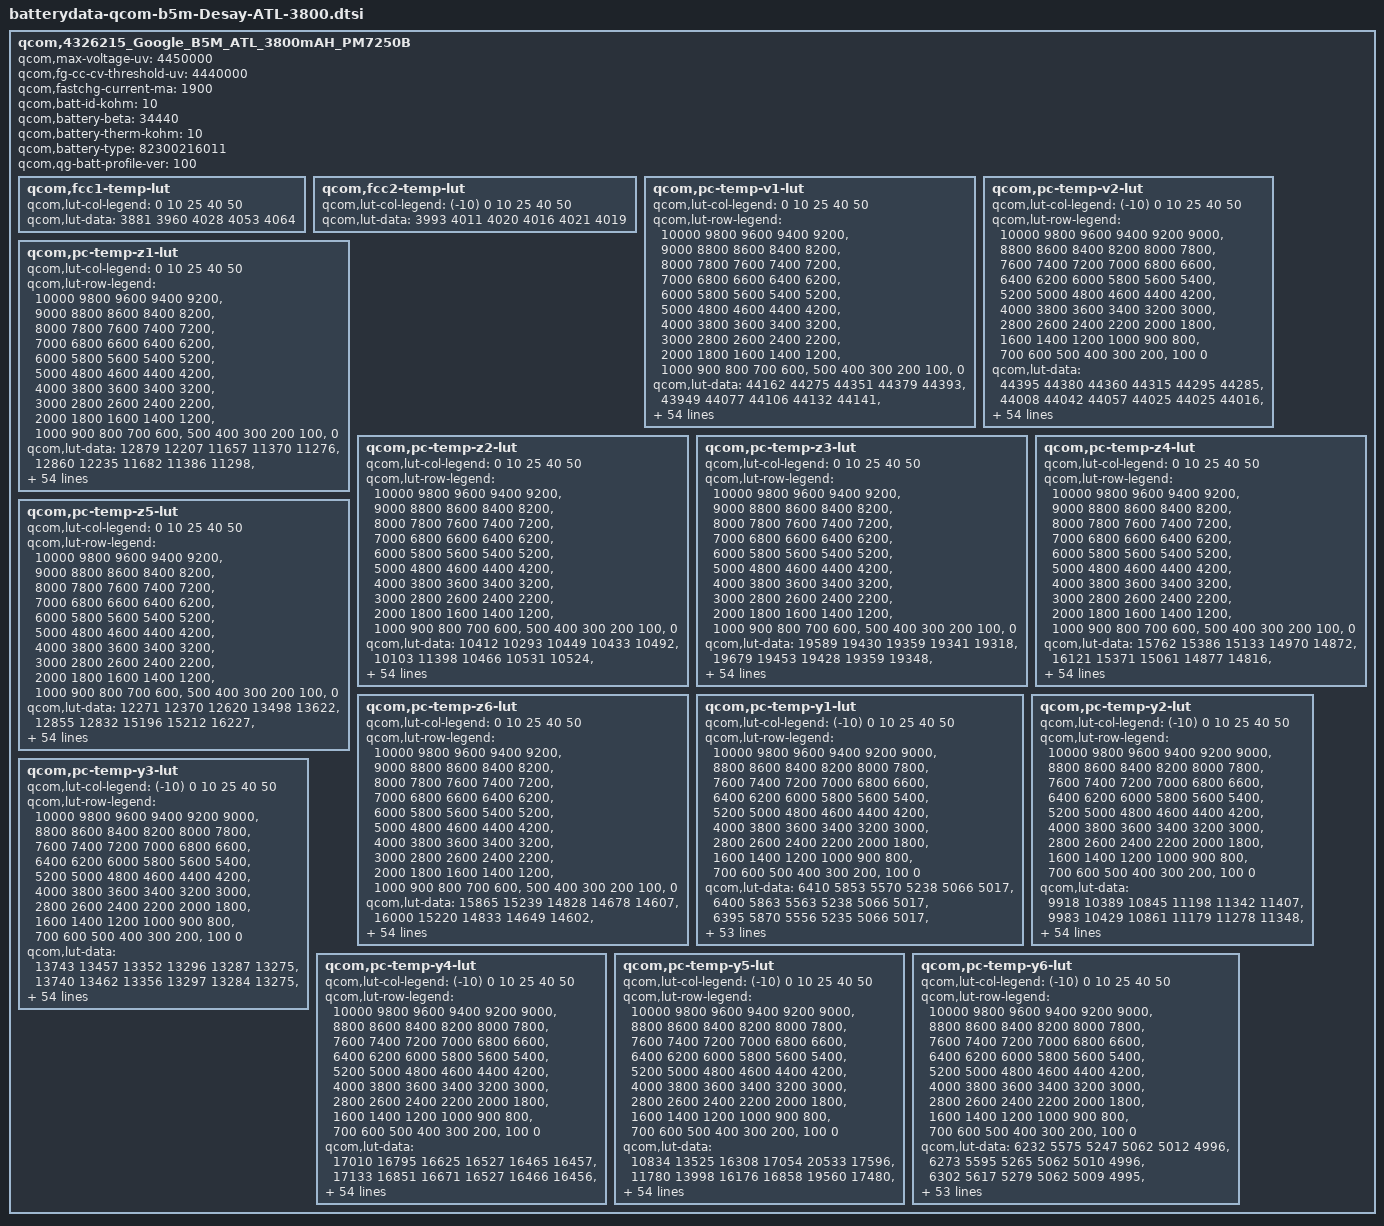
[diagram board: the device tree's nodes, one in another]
// SPDX-License-Identifier: GPL-2.0
qcom,4326215_Google_B5M_ATL_3800mAH_PM7250B {
	/* 4326215_Google_B5M_ATL_3800mAH_PM7250B_Jan23th2020 */
	qcom,max-voltage-uv = <4450000>;
	qcom,fg-cc-cv-threshold-uv = <4440000>;
	qcom,fastchg-current-ma = <1900>;
	qcom,batt-id-kohm = <10>;
	qcom,battery-beta = <34440>;
	qcom,battery-therm-kohm = <10>;
	qcom,battery-type = "82300216011";
	qcom,qg-batt-profile-ver = <100>;

	qcom,fcc1-temp-lut {
		qcom,lut-col-legend = <0 10 25 40 50>;
		qcom,lut-data = <3881 3960 4028 4053 4064>;
	};

	qcom,fcc2-temp-lut {
		qcom,lut-col-legend = <(-10) 0 10 25 40 50>;
		qcom,lut-data = <3993 4011 4020 4016 4021 4019>;
	};

	qcom,pc-temp-v1-lut {
		qcom,lut-col-legend = <0 10 25 40 50>;
		qcom,lut-row-legend = <10000 9800 9600 9400 9200>,
			<9000 8800 8600 8400 8200>,
			<8000 7800 7600 7400 7200>,
			<7000 6800 6600 6400 6200>,
			<6000 5800 5600 5400 5200>,
			<5000 4800 4600 4400 4200>,
			<4000 3800 3600 3400 3200>,
			<3000 2800 2600 2400 2200>,
			<2000 1800 1600 1400 1200>,
			<1000 900 800 700 600>,
			<500 400 300 200 100>,
			<0>;
		qcom,lut-data = <44162 44275 44351 44379 44393>,
			<43949 44077 44106 44132 44141>,
			<43725 43844 43887 43905 43918>,
			<43493 43616 43675 43697 43709>,
			<43258 43401 43453 43481 43498>,
			<43019 43171 43224 43261 43277>,
			<42778 42929 42988 43030 43050>,
			<42536 42687 42747 42789 42816>,
			<42294 42442 42503 42547 42579>,
			<42061 42199 42256 42304 42336>,
			<41836 41963 42013 42062 42093>,
			<41614 41732 41775 41822 41854>,
			<41390 41505 41543 41585 41619>,
			<41170 41280 41314 41354 41387>,
			<40965 41064 41090 41131 41160>,
			<40771 40860 40876 40914 40939>,
			<40573 40663 40671 40703 40726>,
			<40364 40466 40475 40499 40520>,
			<40166 40271 40288 40307 40327>,
			<39999 40086 40107 40122 40143>,
			<39849 39926 39930 39940 39958>,
			<39688 39757 39757 39762 39775>,
			<39518 39509 39552 39568 39581>,
			<39335 39208 39263 39323 39349>,
			<39116 39009 39018 39089 39119>,
			<38890 38882 38896 38937 38955>,
			<38745 38782 38806 38822 38825>,
			<38648 38701 38711 38710 38706>,
			<38573 38631 38616 38601 38596>,
			<38514 38558 38525 38500 38496>,
			<38465 38486 38439 38410 38405>,
			<38418 38417 38360 38329 38321>,
			<38373 38355 38293 38257 38244>,
			<38330 38297 38232 38191 38173>,
			<38289 38248 38179 38129 38104>,
			<38249 38204 38132 38072 38041>,
			<38211 38161 38085 38013 37973>,
			<38174 38124 38042 37952 37896>,
			<38123 38076 37991 37886 37812>,
			<38032 37989 37912 37801 37721>,
			<37917 37870 37801 37696 37621>,
			<37793 37742 37678 37579 37505>,
			<37651 37596 37539 37444 37364>,
			<37481 37428 37377 37287 37209>,
			<37320 37261 37211 37127 37057>,
			<37211 37148 37102 37033 36967>,
			<37182 37117 37075 37008 36947>,
			<37150 37095 37055 36993 36931>,
			<37119 37077 37036 36978 36914>,
			<37078 37039 36999 36931 36859>,
			<36901 36847 36793 36705 36612>,
			<36474 36421 36366 36263 36164>,
			<35885 35835 35787 35682 35583>,
			<35076 35031 34994 34889 34786>,
			<33781 33763 33767 33657 33548>,
			<30000 30000 30000 30000 30000>;
	};

	qcom,pc-temp-v2-lut {
		qcom,lut-col-legend = <(-10) 0 10 25 40 50>;
		qcom,lut-row-legend = <10000 9800 9600 9400 9200 9000>,
			<8800 8600 8400 8200 8000 7800>,
			<7600 7400 7200 7000 6800 6600>,
			<6400 6200 6000 5800 5600 5400>,
			<5200 5000 4800 4600 4400 4200>,
			<4000 3800 3600 3400 3200 3000>,
			<2800 2600 2400 2200 2000 1800>,
			<1600 1400 1200 1000 900 800>,
			<700 600 500 400 300 200>,
			<100 0>;
		qcom,lut-data = <44395 44380 44360 44315 44295 44285>,
			<44008 44042 44057 44025 44025 44016>,
			<43669 43741 43783 43759 43770 43763>,
			<43388 43486 43541 43520 43535 43530>,
			<43152 43268 43328 43304 43318 43314>,
			<42910 43042 43105 43080 43093 43092>,
			<42647 42800 42867 42843 42857 42858>,
			<42390 42554 42625 42603 42618 42621>,
			<42166 42302 42381 42361 42379 42382>,
			<41953 42048 42135 42117 42139 42141>,
			<41696 41810 41894 41878 41901 41903>,
			<41378 41586 41656 41641 41664 41667>,
			<41145 41362 41424 41410 41433 41437>,
			<41040 41127 41192 41184 41204 41211>,
			<40938 40905 40969 40964 40982 40990>,
			<40644 40723 40760 40749 40767 40776>,
			<40127 40560 40560 40540 40558 40567>,
			<39784 40346 40359 40340 40357 40366>,
			<39594 40058 40165 40151 40167 40175>,
			<39415 39773 39953 39959 39978 39986>,
			<39192 39522 39703 39762 39795 39803>,
			<38964 39287 39449 39557 39605 39614>,
			<38762 39072 39226 39328 39376 39387>,
			<38575 38875 39023 39084 39121 39136>,
			<38438 38693 38845 38892 38927 38942>,
			<38344 38521 38689 38745 38783 38795>,
			<38268 38370 38551 38618 38657 38668>,
			<38201 38237 38430 38501 38542 38553>,
			<38142 38125 38319 38396 38437 38449>,
			<38085 38053 38213 38299 38341 38351>,
			<38032 38004 38112 38211 38252 38261>,
			<37977 37959 38022 38128 38171 38177>,
			<37920 37915 37942 38050 38097 38103>,
			<37860 37871 37875 37976 38025 38030>,
			<37798 37823 37828 37912 37953 37952>,
			<37735 37772 37789 37851 37879 37869>,
			<37667 37716 37747 37780 37788 37766>,
			<37593 37656 37703 37698 37678 37640>,
			<37514 37586 37647 37613 37572 37522>,
			<37430 37502 37571 37527 37475 37422>,
			<37337 37403 37476 37440 37383 37329>,
			<37226 37286 37356 37354 37296 37239>,
			<37114 37155 37203 37225 37167 37106>,
			<37013 37000 37046 37096 37040 36978>,
			<36913 36836 36869 36925 36884 36832>,
			<36833 36748 36794 36882 36852 36804>,
			<36794 36722 36767 36866 36842 36791>,
			<36757 36690 36739 36847 36829 36774>,
			<36710 36658 36700 36826 36801 36748>,
			<36632 36593 36624 36760 36726 36657>,
			<36446 36400 36397 36542 36458 36358>,
			<36065 35954 35926 36085 35975 35857>,
			<35513 35307 35276 35462 35338 35210>,
			<34699 34374 34379 34621 34455 34307>,
			<33435 32918 32965 33391 33134 32942>,
			<30879 28130 27743 27850 27863 27776>;
	};

	qcom,pc-temp-z1-lut {
		qcom,lut-col-legend = <0 10 25 40 50>;
		qcom,lut-row-legend = <10000 9800 9600 9400 9200>,
			<9000 8800 8600 8400 8200>,
			<8000 7800 7600 7400 7200>,
			<7000 6800 6600 6400 6200>,
			<6000 5800 5600 5400 5200>,
			<5000 4800 4600 4400 4200>,
			<4000 3800 3600 3400 3200>,
			<3000 2800 2600 2400 2200>,
			<2000 1800 1600 1400 1200>,
			<1000 900 800 700 600>,
			<500 400 300 200 100>,
			<0>;
		qcom,lut-data = <12879 12207 11657 11370 11276>,
			<12860 12235 11682 11386 11298>,
			<12856 12221 11668 11380 11296>,
			<12854 12214 11653 11372 11293>,
			<12853 12204 11639 11366 11290>,
			<12857 12197 11624 11361 11288>,
			<12855 12190 11613 11356 11285>,
			<12844 12183 11604 11351 11283>,
			<12829 12167 11597 11348 11282>,
			<12811 12150 11592 11346 11280>,
			<12789 12135 11588 11344 11279>,
			<12777 12118 11586 11343 11279>,
			<12756 12114 11585 11342 11280>,
			<12731 12115 11583 11341 11280>,
			<12730 12116 11582 11342 11281>,
			<12735 12117 11582 11342 11281>,
			<12737 12117 11583 11343 11282>,
			<12738 12114 11585 11344 11283>,
			<12738 12104 11586 11345 11284>,
			<12728 12100 11588 11348 11286>,
			<12710 12100 11591 11350 11288>,
			<12706 12101 11596 11352 11289>,
			<12723 12103 11600 11354 11290>,
			<12736 12109 11602 11356 11292>,
			<12734 12114 11605 11358 11295>,
			<12729 12123 11610 11362 11298>,
			<12731 12131 11616 11366 11301>,
			<12748 12134 11622 11370 11305>,
			<12757 12137 11628 11375 11309>,
			<12751 12136 11634 11379 11312>,
			<12743 12129 11641 11384 11315>,
			<12742 12127 11648 11389 11318>,
			<12745 12135 11653 11392 11321>,
			<12747 12145 11657 11396 11325>,
			<12753 12153 11661 11400 11328>,
			<12761 12162 11663 11403 11331>,
			<12763 12164 11667 11407 11335>,
			<12762 12161 11677 11411 11337>,
			<12765 12159 11687 11415 11339>,
			<12791 12162 11691 11419 11342>,
			<12819 12170 11693 11422 11344>,
			<12824 12187 11698 11426 11347>,
			<12826 12215 11706 11430 11350>,
			<12826 12215 11715 11434 11353>,
			<12832 12217 11727 11437 11355>,
			<12809 12224 11742 11443 11357>,
			<12826 12223 11735 11444 11358>,
			<12824 12218 11733 11444 11359>,
			<12816 12223 11734 11446 11360>,
			<12850 12223 11740 11450 11362>,
			<12857 12230 11747 11455 11367>,
			<12861 12235 11755 11462 11373>,
			<12867 12273 11766 11471 11381>,
			<12936 12282 11798 11485 11391>,
			<12936 12282 11798 11485 11391>,
			<12936 12282 11798 11485 11391>;
	};

	qcom,pc-temp-z2-lut {
		qcom,lut-col-legend = <0 10 25 40 50>;
		qcom,lut-row-legend = <10000 9800 9600 9400 9200>,
			<9000 8800 8600 8400 8200>,
			<8000 7800 7600 7400 7200>,
			<7000 6800 6600 6400 6200>,
			<6000 5800 5600 5400 5200>,
			<5000 4800 4600 4400 4200>,
			<4000 3800 3600 3400 3200>,
			<3000 2800 2600 2400 2200>,
			<2000 1800 1600 1400 1200>,
			<1000 900 800 700 600>,
			<500 400 300 200 100>,
			<0>;
		qcom,lut-data = <10412 10293 10449 10433 10492>,
			<10103 11398 10466 10531 10524>,
			<10084 10324 10469 10572 10427>,
			<10069 10232 10474 10607 10518>,
			<10053 10213 10440 10594 10611>,
			<10030 10186 10398 10536 10595>,
			<10007 10149 10351 10506 10568>,
			<9988 10122 10305 10489 10501>,
			<9973 10103 10297 10478 10441>,
			<9977 10091 10313 10468 10398>,
			<10025 10096 10331 10461 10366>,
			<10055 10115 10344 10472 10359>,
			<10016 10132 10357 10495 10357>,
			<9964 10145 10369 10488 10362>,
			<9966 10160 10380 10416 10372>,
			<9996 10176 10388 10377 10385>,
			<10015 10193 10399 10382 10406>,
			<10020 10211 10407 10391 10432>,
			<10026 10231 10413 10399 10458>,
			<10042 10241 10422 10414 10484>,
			<10069 10244 10435 10446 10502>,
			<10085 10245 10452 10532 10517>,
			<10095 10252 10458 10577 10531>,
			<10102 10264 10460 10504 10543>,
			<10108 10265 10460 10420 10562>,
			<10113 10247 10437 10452 10648>,
			<10121 10234 10398 10549 10840>,
			<10131 10245 10418 10591 10880>,
			<10141 10264 10525 10607 10698>,
			<10146 10276 10571 10613 10519>,
			<10150 10286 10520 10553 10422>,
			<10156 10290 10468 10479 10361>,
			<10162 10288 10459 10480 10364>,
			<10168 10287 10455 10502 10397>,
			<10173 10289 10462 10535 10436>,
			<10177 10297 10500 10598 10501>,
			<10179 10302 10532 10667 10576>,
			<10181 10306 10549 10735 10700>,
			<10185 10310 10564 10793 10823>,
			<10195 10327 10588 10825 10811>,
			<10204 10346 10615 10848 10737>,
			<10207 10347 10620 10847 10706>,
			<10208 10339 10611 10800 10713>,
			<10226 10346 10609 10782 10695>,
			<10347 10404 10625 10780 10645>,
			<10443 10540 10696 10686 10652>,
			<10278 10530 10666 10647 10655>,
			<10197 10556 10633 10643 10655>,
			<9966 10648 10612 10668 10709>,
			<9761 10689 10634 10739 10766>,
			<9802 10727 10735 10651 10542>,
			<9777 10668 10810 10518 10406>,
			<9781 10558 10844 10449 10366>,
			<9675 10388 10726 10398 10291>,
			<9675 10388 10726 10398 10291>,
			<9675 10388 10726 10398 10291>;
	};

	qcom,pc-temp-z3-lut {
		qcom,lut-col-legend = <0 10 25 40 50>;
		qcom,lut-row-legend = <10000 9800 9600 9400 9200>,
			<9000 8800 8600 8400 8200>,
			<8000 7800 7600 7400 7200>,
			<7000 6800 6600 6400 6200>,
			<6000 5800 5600 5400 5200>,
			<5000 4800 4600 4400 4200>,
			<4000 3800 3600 3400 3200>,
			<3000 2800 2600 2400 2200>,
			<2000 1800 1600 1400 1200>,
			<1000 900 800 700 600>,
			<500 400 300 200 100>,
			<0>;
		qcom,lut-data = <19589 19430 19359 19341 19318>,
			<19679 19453 19428 19359 19348>,
			<19776 19612 19445 19376 19345>,
			<19842 19647 19497 19405 19364>,
			<19871 19659 19513 19422 19393>,
			<19889 19667 19520 19426 19401>,
			<19898 19674 19517 19426 19401>,
			<19900 19676 19511 19424 19391>,
			<19900 19675 19504 19422 19381>,
			<19901 19672 19497 19412 19376>,
			<19909 19663 19489 19401 19372>,
			<19912 19642 19476 19397 19367>,
			<19897 19630 19465 19394 19360>,
			<19871 19623 19460 19388 19355>,
			<19847 19617 19457 19373 19351>,
			<19820 19611 19452 19364 19349>,
			<19810 19605 19441 19363 19347>,
			<19810 19597 19433 19362 19345>,
			<19809 19588 19430 19360 19341>,
			<19799 19584 19427 19359 19335>,
			<19775 19584 19428 19359 19333>,
			<19769 19585 19432 19362 19338>,
			<19780 19592 19435 19364 19341>,
			<19790 19607 19442 19357 19332>,
			<19795 19610 19446 19348 19321>,
			<19799 19598 19432 19343 19334>,
			<19799 19584 19409 19339 19376>,
			<19794 19576 19409 19344 19389>,
			<19787 19570 19428 19384 19387>,
			<19779 19572 19447 19408 19384>,
			<19770 19585 19464 19403 19376>,
			<19764 19594 19475 19395 19364>,
			<19758 19597 19471 19387 19356>,
			<19755 19599 19462 19379 19350>,
			<19753 19597 19454 19374 19346>,
			<19751 19591 19448 19369 19342>,
			<19748 19586 19444 19368 19341>,
			<19743 19580 19441 19368 19343>,
			<19737 19574 19439 19369 19347>,
			<19729 19567 19435 19369 19346>,
			<19720 19560 19430 19368 19344>,
			<19711 19555 19426 19365 19344>,
			<19699 19551 19421 19360 19346>,
			<19679 19542 19417 19360 19346>,
			<19619 19519 19411 19362 19342>,
			<19462 19476 19394 19344 19333>,
			<19354 19472 19393 19345 19326>,
			<19327 19456 19389 19342 19325>,
			<19299 19363 19385 19335 19320>,
			<19276 19346 19367 19329 19321>,
			<19267 19349 19377 19344 19341>,
			<19300 19337 19350 19354 19347>,
			<19332 19321 19333 19357 19348>,
			<19343 19318 19342 19361 19353>,
			<19343 19318 19342 19361 19353>,
			<19343 19318 19342 19361 19353>;
	};

	qcom,pc-temp-z4-lut {
		qcom,lut-col-legend = <0 10 25 40 50>;
		qcom,lut-row-legend = <10000 9800 9600 9400 9200>,
			<9000 8800 8600 8400 8200>,
			<8000 7800 7600 7400 7200>,
			<7000 6800 6600 6400 6200>,
			<6000 5800 5600 5400 5200>,
			<5000 4800 4600 4400 4200>,
			<4000 3800 3600 3400 3200>,
			<3000 2800 2600 2400 2200>,
			<2000 1800 1600 1400 1200>,
			<1000 900 800 700 600>,
			<500 400 300 200 100>,
			<0>;
		qcom,lut-data = <15762 15386 15133 14970 14872>,
			<16121 15371 15061 14877 14816>,
			<16058 15522 14960 14820 14773>,
			<15811 15451 15098 14871 14782>,
			<15618 15269 15037 14883 14825>,
			<15457 15151 14950 14841 14791>,
			<15323 15065 14903 14806 14767>,
			<15221 14997 14866 14774 14753>,
			<15138 14941 14834 14756 14742>,
			<15057 14895 14802 14750 14735>,
			<14971 14859 14783 14746 14729>,
			<14920 14828 14774 14736 14723>,
			<14903 14810 14768 14724 14718>,
			<14892 14799 14758 14720 14712>,
			<14875 14791 14745 14719 14704>,
			<14849 14780 14738 14717 14696>,
			<14835 14772 14735 14709 14686>,
			<14831 14772 14732 14697 14678>,
			<14828 14775 14725 14688 14673>,
			<14824 14777 14719 14681 14669>,
			<14817 14762 14719 14680 14668>,
			<14811 14746 14721 14684 14673>,
			<14803 14786 14731 14693 14682>,
			<14798 14888 14824 14768 14744>,
			<14841 14926 14901 14849 14821>,
			<14922 14935 14903 14853 14810>,
			<14942 14938 14903 14847 14756>,
			<14941 14927 14895 14832 14724>,
			<14939 14902 14854 14771 14708>,
			<14927 14877 14815 14726 14699>,
			<14907 14846 14778 14714 14694>,
			<14890 14824 14754 14707 14690>,
			<14873 14809 14750 14701 14684>,
			<14858 14800 14748 14696 14678>,
			<14845 14797 14748 14696 14677>,
			<14833 14795 14749 14698 14679>,
			<14820 14792 14751 14701 14683>,
			<14805 14787 14753 14709 14694>,
			<14799 14783 14756 14718 14705>,
			<14797 14784 14762 14723 14706>,
			<14795 14786 14769 14727 14706>,
			<14788 14782 14768 14727 14704>,
			<14773 14763 14754 14721 14695>,
			<14760 14749 14744 14716 14695>,
			<14753 14729 14733 14711 14699>,
			<14823 14697 14694 14688 14677>,
			<14941 14691 14684 14677 14671>,
			<14966 14696 14667 14660 14651>,
			<14987 14787 14657 14647 14638>,
			<15002 14801 14670 14653 14637>,
			<15006 14807 14680 14659 14639>,
			<14995 14831 14719 14657 14639>,
			<14978 14854 14738 14654 14638>,
			<14987 14865 14731 14651 14633>,
			<14987 14865 14731 14651 14633>,
			<14987 14865 14731 14651 14633>;
	};

	qcom,pc-temp-z5-lut {
		qcom,lut-col-legend = <0 10 25 40 50>;
		qcom,lut-row-legend = <10000 9800 9600 9400 9200>,
			<9000 8800 8600 8400 8200>,
			<8000 7800 7600 7400 7200>,
			<7000 6800 6600 6400 6200>,
			<6000 5800 5600 5400 5200>,
			<5000 4800 4600 4400 4200>,
			<4000 3800 3600 3400 3200>,
			<3000 2800 2600 2400 2200>,
			<2000 1800 1600 1400 1200>,
			<1000 900 800 700 600>,
			<500 400 300 200 100>,
			<0>;
		qcom,lut-data = <12271 12370 12620 13498 13622>,
			<12855 12832 15196 15212 16227>,
			<13441 14638 17001 17601 17130>,
			<14178 15226 15937 17602 18662>,
			<14739 15715 16525 17395 18262>,
			<15166 16254 17258 17735 19519>,
			<15622 16850 17453 18235 19819>,
			<16183 17527 17551 19181 19231>,
			<16783 18400 17869 19605 18807>,
			<17522 19276 18886 19101 18826>,
			<18741 19933 19469 18580 18871>,
			<19583 20520 19266 18845 18688>,
			<19925 21135 19030 19450 18310>,
			<20188 21795 19394 19377 18219>,
			<20469 22480 20407 18205 18471>,
			<21046 23363 20687 17572 18849>,
			<21908 24141 20430 18125 19739>,
			<23772 24203 20254 19075 20658>,
			<25260 24021 20682 19959 20662>,
			<24820 23998 21679 20971 20445>,
			<23653 26219 23242 22346 20701>,
			<23935 30062 25745 24514 23551>,
			<30727 35285 27447 25512 25467>,
			<37839 41670 28692 22936 21587>,
			<41162 42443 29362 19136 16410>,
			<43607 34873 25565 16806 16453>,
			<43438 27754 19132 14977 18238>,
			<39674 24709 18173 15020 19808>,
			<35804 22760 18627 18194 21307>,
			<33163 22924 19523 21084 22047>,
			<31151 24965 23507 22378 21909>,
			<30579 27407 27991 23413 21718>,
			<30359 30491 30173 24536 22063>,
			<30353 33415 31727 25659 23366>,
			<31260 35191 32844 26913 24595>,
			<32567 36537 33832 28550 25851>,
			<33297 36878 34197 29359 26566>,
			<34046 36302 33575 29196 26685>,
			<34645 35530 32355 28791 26743>,
			<35222 34190 30205 27488 25845>,
			<35590 32479 27064 24620 23134>,
			<34631 31845 25547 22753 22302>,
			<32155 31607 24932 21659 22850>,
			<30452 30278 24057 21308 22198>,
			<26725 29273 23437 21176 19916>,
			<17720 28760 25668 20481 20287>,
			<12744 26637 25899 21750 19193>,
			<11828 22385 26812 23292 21956>,
			<11538 13967 27355 24606 24930>,
			<11315 13049 21421 21938 25073>,
			<11341 13183 19714 20306 25180>,
			<11527 12669 15316 20559 25094>,
			<11701 12154 13647 20896 24773>,
			<11662 11957 13824 21171 26887>,
			<11662 11957 13824 21171 26887>,
			<11662 11957 13824 21171 26887>;
	};

	qcom,pc-temp-z6-lut {
		qcom,lut-col-legend = <0 10 25 40 50>;
		qcom,lut-row-legend = <10000 9800 9600 9400 9200>,
			<9000 8800 8600 8400 8200>,
			<8000 7800 7600 7400 7200>,
			<7000 6800 6600 6400 6200>,
			<6000 5800 5600 5400 5200>,
			<5000 4800 4600 4400 4200>,
			<4000 3800 3600 3400 3200>,
			<3000 2800 2600 2400 2200>,
			<2000 1800 1600 1400 1200>,
			<1000 900 800 700 600>,
			<500 400 300 200 100>,
			<0>;
		qcom,lut-data = <15865 15239 14828 14678 14607>,
			<16000 15220 14833 14649 14602>,
			<15973 15341 14792 14634 14582>,
			<15861 15309 14873 14669 14595>,
			<15764 15218 14850 14681 14626>,
			<15674 15157 14815 14665 14618>,
			<15596 15111 14790 14651 14609>,
			<15530 15072 14768 14637 14597>,
			<15474 15038 14748 14625 14587>,
			<15427 15008 14730 14617 14581>,
			<15386 14977 14715 14609 14576>,
			<15351 14949 14705 14602 14570>,
			<15323 14932 14696 14596 14564>,
			<15299 14923 14688 14589 14558>,
			<15270 14915 14681 14582 14553>,
			<15240 14907 14674 14575 14548>,
			<15227 14899 14667 14570 14543>,
			<15225 14894 14662 14565 14538>,
			<15223 14891 14657 14560 14533>,
			<15215 14887 14654 14556 14528>,
			<15202 14881 14654 14556 14528>,
			<15198 14877 14657 14559 14531>,
			<15202 14899 14665 14566 14538>,
			<15209 14954 14710 14595 14562>,
			<15232 14971 14746 14625 14588>,
			<15268 14970 14742 14625 14591>,
			<15277 14968 14732 14622 14589>,
			<15278 14960 14726 14619 14587>,
			<15277 14949 14721 14614 14581>,
			<15270 14941 14717 14609 14574>,
			<15259 14935 14712 14602 14567>,
			<15250 14932 14708 14595 14560>,
			<15242 14930 14704 14589 14553>,
			<15236 14928 14700 14582 14547>,
			<15232 14927 14698 14580 14545>,
			<15229 14925 14696 14580 14545>,
			<15226 14924 14696 14579 14545>,
			<15224 14922 14697 14583 14550>,
			<15223 14921 14698 14588 14557>,
			<15226 14922 14700 14591 14558>,
			<15230 14924 14702 14592 14557>,
			<15229 14924 14701 14592 14556>,
			<15228 14921 14695 14586 14554>,
			<15222 14917 14691 14585 14554>,
			<15199 14907 14687 14586 14555>,
			<15164 14880 14665 14567 14541>,
			<15158 14877 14661 14562 14535>,
			<15157 14871 14653 14553 14526>,
			<15156 14867 14646 14544 14517>,
			<15158 14867 14646 14544 14517>,
			<15166 14878 14657 14556 14530>,
			<15185 14889 14664 14562 14535>,
			<15206 14900 14668 14565 14537>,
			<15237 14917 14675 14568 14541>,
			<15237 14917 14675 14568 14541>,
			<15237 14917 14675 14568 14541>;
	};

	qcom,pc-temp-y1-lut {
		qcom,lut-col-legend = <(-10) 0 10 25 40 50>;
		qcom,lut-row-legend = <10000 9800 9600 9400 9200 9000>,
			<8800 8600 8400 8200 8000 7800>,
			<7600 7400 7200 7000 6800 6600>,
			<6400 6200 6000 5800 5600 5400>,
			<5200 5000 4800 4600 4400 4200>,
			<4000 3800 3600 3400 3200 3000>,
			<2800 2600 2400 2200 2000 1800>,
			<1600 1400 1200 1000 900 800>,
			<700 600 500 400 300 200>,
			<100 0>;
		qcom,lut-data = <6410 5853 5570 5238 5066 5017>,
			<6400 5863 5563 5238 5066 5017>,
			<6395 5870 5556 5235 5066 5017>,
			<6391 5875 5551 5232 5065 5017>,
			<6390 5878 5547 5229 5064 5016>,
			<6390 5878 5545 5227 5063 5016>,
			<6396 5874 5545 5225 5061 5014>,
			<6402 5872 5546 5223 5059 5013>,
			<6412 5876 5543 5220 5058 5013>,
			<6428 5885 5540 5216 5057 5013>,
			<6430 5890 5541 5212 5056 5013>,
			<6422 5895 5547 5206 5054 5013>,
			<6414 5896 5550 5204 5053 5013>,
			<6404 5893 5549 5206 5053 5012>,
			<6396 5888 5547 5208 5054 5011>,
			<6396 5883 5543 5207 5054 5011>,
			<6398 5877 5538 5205 5053 5012>,
			<6402 5877 5537 5205 5053 5012>,
			<6419 5889 5538 5207 5053 5012>,
			<6432 5896 5539 5209 5052 5012>,
			<6431 5892 5538 5211 5053 5013>,
			<6425 5887 5538 5213 5055 5014>,
			<6422 5887 5539 5216 5056 5014>,
			<6416 5889 5541 5220 5058 5015>,
			<6415 5891 5542 5224 5060 5016>,
			<6436 5898 5544 5227 5063 5018>,
			<6457 5903 5546 5229 5065 5020>,
			<6455 5903 5549 5233 5066 5021>,
			<6451 5902 5552 5237 5067 5022>,
			<6447 5901 5553 5242 5069 5023>,
			<6444 5899 5554 5247 5072 5025>,
			<6438 5900 5555 5253 5076 5027>,
			<6419 5902 5560 5258 5079 5030>,
			<6399 5904 5565 5263 5082 5032>,
			<6404 5906 5570 5266 5085 5034>,
			<6422 5907 5575 5270 5088 5036>,
			<6430 5909 5579 5273 5091 5038>,
			<6429 5915 5583 5277 5093 5039>,
			<6427 5918 5587 5281 5095 5041>,
			<6423 5919 5590 5288 5098 5043>,
			<6417 5919 5592 5292 5100 5045>,
			<6408 5914 5588 5291 5101 5047>,
			<6432 5932 5598 5301 5106 5048>,
			<6464 5953 5610 5297 5107 5050>,
			<6490 5973 5610 5305 5112 5052>,
			<6495 5957 5604 5313 5111 5054>,
			<6480 5937 5614 5311 5113 5054>,
			<6485 5952 5611 5313 5114 5054>,
			<6509 5966 5619 5317 5113 5054>,
			<6569 5988 5612 5322 5114 5055>,
			<6618 5981 5619 5326 5116 5057>,
			<6641 6006 5634 5332 5119 5060>,
			<6728 6097 5651 5347 5126 5067>,
			<6812 6167 5695 5356 5134 5072>,
			<6812 6167 5695 5356 5134 5072>,
			<6812 6167 5695 5356 5134 5072>;
	};

	qcom,pc-temp-y2-lut {
		qcom,lut-col-legend = <(-10) 0 10 25 40 50>;
		qcom,lut-row-legend = <10000 9800 9600 9400 9200 9000>,
			<8800 8600 8400 8200 8000 7800>,
			<7600 7400 7200 7000 6800 6600>,
			<6400 6200 6000 5800 5600 5400>,
			<5200 5000 4800 4600 4400 4200>,
			<4000 3800 3600 3400 3200 3000>,
			<2800 2600 2400 2200 2000 1800>,
			<1600 1400 1200 1000 900 800>,
			<700 600 500 400 300 200>,
			<100 0>;
		qcom,lut-data = <9918 10389 10845 11198 11342 11407>,
			<9983 10429 10861 11179 11278 11348>,
			<10063 10486 10868 11157 11199 11288>,
			<10142 10545 10868 11131 11123 11231>,
			<10205 10587 10864 11102 11066 11178>,
			<10237 10598 10857 11071 11046 11132>,
			<10248 10590 10838 11030 11049 11090>,
			<10260 10583 10817 11001 11051 11052>,
			<10312 10589 10796 10997 11035 11011>,
			<10392 10601 10778 10996 11013 10976>,
			<10415 10606 10776 10997 11017 10974>,
			<10403 10602 10781 11001 11054 10991>,
			<10394 10606 10788 11004 11078 11011>,
			<10395 10676 10802 11011 11090 11042>,
			<10390 10748 10825 11021 11096 11065>,
			<10223 10748 10868 11038 11081 11055>,
			<9810 10728 10933 11068 11048 11031>,
			<9679 10743 10984 11108 11051 11032>,
			<9677 10813 11032 11174 11123 11096>,
			<9675 10852 11051 11230 11219 11159>,
			<9672 10846 11034 11275 11377 11268>,
			<9669 10833 11014 11306 11509 11374>,
			<9667 10821 11013 11285 11454 11346>,
			<9666 10806 11017 11224 11296 11255>,
			<9664 10782 11021 11207 11252 11230>,
			<9663 10727 11026 11230 11265 11247>,
			<9662 10670 11033 11256 11282 11275>,
			<9662 10505 11044 11274 11307 11342>,
			<9661 10270 11056 11294 11336 11425>,
			<9660 10144 11047 11324 11359 11458>,
			<9660 9880 11010 11366 11391 11479>,
			<9659 9744 10991 11386 11422 11487>,
			<9659 9709 10986 11392 11488 11515>,
			<9659 9690 10980 11394 11540 11541>,
			<9658 9680 10964 11387 11555 11548>,
			<9658 9675 10935 11367 11566 11553>,
			<9658 9670 10901 11341 11549 11530>,
			<9658 9666 10851 11302 11474 11459>,
			<9658 9663 10791 11284 11420 11427>,
			<9657 9661 10713 11296 11388 11437>,
			<9657 9659 10621 11297 11376 11441>,
			<9657 9658 10512 11265 11390 11438>,
			<9657 9658 10217 11254 11438 11417>,
			<9656 9658 10155 11279 11413 11372>,
			<9656 9657 9849 11143 11393 11450>,
			<9655 9655 9740 11108 11273 11194>,
			<9655 9655 9717 11083 11282 11184>,
			<9654 9655 9695 11080 11287 11151>,
			<9653 9654 9683 11056 11270 11118>,
			<9651 9654 9672 11047 11156 11086>,
			<9649 9653 9666 10994 11127 11052>,
			<9648 9651 9661 10956 11134 11024>,
			<9648 9649 9656 10896 11045 10972>,
			<9648 9648 9653 10819 10989 10858>,
			<9648 9648 9653 10819 10989 10858>,
			<9648 9648 9653 10819 10989 10858>;
	};

	qcom,pc-temp-y3-lut {
		qcom,lut-col-legend = <(-10) 0 10 25 40 50>;
		qcom,lut-row-legend = <10000 9800 9600 9400 9200 9000>,
			<8800 8600 8400 8200 8000 7800>,
			<7600 7400 7200 7000 6800 6600>,
			<6400 6200 6000 5800 5600 5400>,
			<5200 5000 4800 4600 4400 4200>,
			<4000 3800 3600 3400 3200 3000>,
			<2800 2600 2400 2200 2000 1800>,
			<1600 1400 1200 1000 900 800>,
			<700 600 500 400 300 200>,
			<100 0>;
		qcom,lut-data = <13743 13457 13352 13296 13287 13275>,
			<13740 13462 13356 13297 13284 13275>,
			<13736 13468 13360 13298 13281 13275>,
			<13730 13473 13364 13299 13280 13275>,
			<13723 13477 13368 13300 13279 13276>,
			<13715 13480 13370 13302 13279 13276>,
			<13703 13482 13372 13303 13280 13277>,
			<13695 13483 13373 13305 13281 13278>,
			<13693 13483 13375 13305 13284 13279>,
			<13691 13484 13376 13304 13288 13280>,
			<13670 13485 13378 13305 13290 13280>,
			<13578 13494 13380 13305 13291 13281>,
			<13528 13497 13380 13306 13291 13281>,
			<13536 13458 13380 13310 13291 13285>,
			<13549 13416 13379 13313 13291 13287>,
			<13558 13421 13372 13312 13290 13287>,
			<13566 13437 13359 13310 13288 13287>,
			<13573 13439 13357 13309 13288 13287>,
			<13582 13431 13361 13308 13290 13287>,
			<13587 13420 13363 13308 13292 13287>,
			<13584 13410 13357 13309 13294 13288>,
			<13578 13399 13349 13310 13296 13289>,
			<13573 13391 13344 13308 13293 13287>,
			<13568 13383 13340 13301 13285 13280>,
			<13567 13378 13337 13298 13282 13277>,
			<13588 13376 13334 13297 13281 13275>,
			<13622 13372 13332 13296 13281 13274>,
			<13657 13361 13331 13295 13280 13275>,
			<13700 13347 13330 13295 13279 13276>,
			<13746 13348 13329 13295 13279 13276>,
			<13798 13361 13327 13296 13279 13275>,
			<13852 13377 13326 13296 13279 13275>,
			<13908 13396 13325 13295 13279 13276>,
			<13966 13418 13324 13294 13280 13276>,
			<14027 13445 13325 13295 13280 13277>,
			<14092 13478 13328 13296 13281 13276>,
			<14153 13519 13332 13296 13281 13276>,
			<14210 13575 13336 13295 13279 13275>,
			<14264 13641 13340 13293 13278 13274>,
			<14317 13719 13343 13290 13278 13273>,
			<14363 13804 13346 13290 13278 13273>,
			<14399 13893 13351 13294 13278 13275>,
			<14433 13965 13352 13294 13277 13273>,
			<14410 13943 13347 13293 13278 13274>,
			<14518 14089 13360 13292 13275 13273>,
			<14677 14285 13395 13298 13278 13276>,
			<14779 14401 13415 13299 13280 13277>,
			<14945 14503 13446 13301 13285 13279>,
			<15191 14633 13483 13309 13288 13284>,
			<15759 14791 13544 13313 13289 13284>,
			<17535 15039 13622 13315 13283 13280>,
			<21585 15627 13763 13316 13287 13280>,
			<31175 17835 14077 13321 13290 13284>,
			<60583 25719 14687 13330 13293 13287>,
			<60583 25719 14687 13330 13293 13287>,
			<60583 25719 14687 13330 13293 13287>;
	};

	qcom,pc-temp-y4-lut {
		qcom,lut-col-legend = <(-10) 0 10 25 40 50>;
		qcom,lut-row-legend = <10000 9800 9600 9400 9200 9000>,
			<8800 8600 8400 8200 8000 7800>,
			<7600 7400 7200 7000 6800 6600>,
			<6400 6200 6000 5800 5600 5400>,
			<5200 5000 4800 4600 4400 4200>,
			<4000 3800 3600 3400 3200 3000>,
			<2800 2600 2400 2200 2000 1800>,
			<1600 1400 1200 1000 900 800>,
			<700 600 500 400 300 200>,
			<100 0>;
		qcom,lut-data = <17010 16795 16625 16527 16465 16457>,
			<17133 16851 16671 16527 16466 16456>,
			<17294 16955 16724 16526 16466 16454>,
			<17451 17070 16774 16525 16467 16453>,
			<17564 17156 16808 16524 16468 16452>,
			<17593 17179 16816 16523 16469 16452>,
			<17571 17175 16807 16521 16469 16451>,
			<17543 17169 16795 16521 16470 16451>,
			<17524 17154 16784 16523 16468 16452>,
			<17509 17133 16775 16529 16466 16454>,
			<17520 17125 16773 16534 16466 16457>,
			<17602 17121 16772 16541 16471 16462>,
			<17683 17126 16772 16548 16477 16465>,
			<17763 17221 16780 16553 16484 16467>,
			<17823 17325 16796 16560 16493 16469>,
			<17704 17344 16845 16574 16505 16474>,
			<17362 17343 16922 16598 16520 16484>,
			<17204 17311 16938 16625 16534 16494>,
			<17163 17177 16929 16663 16546 16506>,
			<17123 17051 16913 16681 16561 16519>,
			<17043 16978 16855 16679 16583 16539>,
			<16952 16918 16774 16675 16600 16555>,
			<16891 16860 16717 16640 16575 16537>,
			<16843 16807 16667 16553 16505 16485>,
			<16827 16750 16637 16518 16478 16464>,
			<16832 16680 16618 16508 16471 16460>,
			<16837 16633 16605 16505 16468 16458>,
			<16838 16628 16599 16508 16472 16460>,
			<16840 16635 16595 16515 16479 16464>,
			<16840 16646 16585 16521 16487 16470>,
			<16841 16665 16570 16530 16497 16479>,
			<16842 16684 16557 16538 16507 16489>,
			<16848 16701 16544 16546 16521 16502>,
			<16857 16719 16537 16552 16531 16509>,
			<16863 16737 16546 16557 16532 16510>,
			<16868 16754 16568 16560 16533 16511>,
			<16874 16772 16592 16555 16527 16506>,
			<16881 16792 16621 16529 16500 16484>,
			<16885 16800 16644 16509 16481 16470>,
			<16879 16800 16661 16499 16470 16465>,
			<16868 16797 16667 16497 16468 16464>,
			<16854 16773 16667 16509 16473 16465>,
			<16839 16751 16657 16505 16465 16457>,
			<16807 16713 16631 16500 16465 16457>,
			<16812 16705 16641 16488 16448 16437>,
			<16819 16718 16666 16503 16459 16448>,
			<16836 16723 16683 16517 16469 16457>,
			<16849 16746 16707 16537 16473 16467>,
			<16875 16781 16744 16555 16488 16485>,
			<16919 16824 16789 16566 16498 16489>,
			<17121 16837 16796 16561 16476 16456>,
			<17708 16832 16795 16555 16461 16450>,
			<19915 17171 16831 16570 16468 16458>,
			<36747 20404 16906 16620 16498 16486>,
			<36747 20404 16906 16620 16498 16486>,
			<36747 20404 16906 16620 16498 16486>;
	};

	qcom,pc-temp-y5-lut {
		qcom,lut-col-legend = <(-10) 0 10 25 40 50>;
		qcom,lut-row-legend = <10000 9800 9600 9400 9200 9000>,
			<8800 8600 8400 8200 8000 7800>,
			<7600 7400 7200 7000 6800 6600>,
			<6400 6200 6000 5800 5600 5400>,
			<5200 5000 4800 4600 4400 4200>,
			<4000 3800 3600 3400 3200 3000>,
			<2800 2600 2400 2200 2000 1800>,
			<1600 1400 1200 1000 900 800>,
			<700 600 500 400 300 200>,
			<100 0>;
		qcom,lut-data = <10834 13525 16308 17054 20533 17596>,
			<11780 13998 16176 16858 19560 17480>,
			<12756 14462 16144 16596 18091 17246>,
			<13670 14888 16171 16318 16546 16977>,
			<14429 15248 16221 16075 15343 16758>,
			<14945 15516 16261 15918 14864 16665>,
			<15257 15751 16361 15816 14682 16621>,
			<15558 15875 16437 15671 14600 16562>,
			<16242 15850 16375 15258 15414 16403>,
			<17112 15798 16220 14667 16814 16117>,
			<16853 15876 16049 14295 16946 15746>,
			<14559 16344 15831 13980 16428 15220>,
			<13316 16507 15566 13872 15847 15038>,
			<15541 15029 15214 14029 15269 15814>,
			<18145 13503 14837 14185 14659 16590>,
			<17302 14634 14447 13883 13943 16207>,
			<14542 17442 14089 13223 13257 15252>,
			<13808 18436 14340 13082 13140 14732>,
			<15024 18652 16330 13212 13245 14310>,
			<15918 18835 18035 13477 13453 14146>,
			<15674 19074 18848 15551 14668 14787>,
			<15082 19333 19437 18109 16270 15841>,
			<14172 19572 19903 18847 17159 16824>,
			<12653 19809 20295 19285 17822 17858>,
			<11870 20130 20342 19341 18023 18005>,
			<11635 20692 20007 19070 18043 17035>,
			<11523 21036 19779 18720 17992 16289>,
			<11555 17977 20051 18244 17255 16357>,
			<11634 13109 20497 17786 16238 16535>,
			<11729 12317 20767 17888 15961 16300>,
			<11959 12298 21047 18428 15830 15623>,
			<12153 12346 21033 18635 15812 15381>,
			<12235 12523 19788 18507 15944 15596>,
			<12305 12733 18586 18394 16170 15934>,
			<12431 12877 18231 19224 17029 16446>,
			<12609 13004 17892 20716 18189 17025>,
			<12725 13147 17683 20908 18322 17235>,
			<12804 13317 17593 20448 18156 17329>,
			<12879 13397 17424 19711 18022 17355>,
			<12974 13407 16962 17513 17976 17077>,
			<13031 13408 16596 16565 17862 17000>,
			<12606 13394 16389 16988 17185 17181>,
			<12161 13298 15330 16930 16566 16181>,
			<11878 12826 14677 17353 16386 16263>,
			<11681 12499 13526 17215 17272 19625>,
			<11769 12329 13357 18093 16023 17123>,
			<11676 12711 13310 16774 15513 16012>,
			<11918 12491 13252 15538 16771 16265>,
			<12102 12554 13037 15874 16615 17483>,
			<12321 12543 13045 15918 16426 16905>,
			<11557 12582 13163 17466 15818 17215>,
			<10181 12377 13133 19023 19564 18194>,
			<9361 11134 13065 19277 21637 22409>,
			<8895 9482 12816 19767 22250 23364>,
			<8895 9482 12816 19767 22250 23364>,
			<8895 9482 12816 19767 22250 23364>;
	};

	qcom,pc-temp-y6-lut {
		qcom,lut-col-legend = <(-10) 0 10 25 40 50>;
		qcom,lut-row-legend = <10000 9800 9600 9400 9200 9000>,
			<8800 8600 8400 8200 8000 7800>,
			<7600 7400 7200 7000 6800 6600>,
			<6400 6200 6000 5800 5600 5400>,
			<5200 5000 4800 4600 4400 4200>,
			<4000 3800 3600 3400 3200 3000>,
			<2800 2600 2400 2200 2000 1800>,
			<1600 1400 1200 1000 900 800>,
			<700 600 500 400 300 200>,
			<100 0>;
		qcom,lut-data = <6232 5575 5247 5062 5012 4996>,
			<6273 5595 5265 5062 5010 4996>,
			<6302 5617 5279 5062 5009 4995>,
			<6320 5636 5289 5062 5008 4995>,
			<6328 5649 5294 5062 5008 4996>,
			<6329 5652 5295 5062 5008 4996>,
			<6310 5649 5290 5062 5009 4996>,
			<6289 5643 5284 5062 5010 4997>,
			<6281 5633 5278 5062 5011 4998>,
			<6275 5623 5273 5063 5013 4999>,
			<6261 5620 5270 5064 5015 5001>,
			<6227 5620 5268 5066 5016 5002>,
			<6211 5620 5267 5069 5018 5004>,
			<6243 5621 5268 5072 5021 5006>,
			<6281 5622 5270 5076 5023 5009>,
			<6237 5629 5277 5081 5026 5011>,
			<6114 5642 5290 5085 5029 5013>,
			<6073 5640 5292 5092 5032 5016>,
			<6072 5600 5291 5102 5037 5019>,
			<6071 5561 5290 5107 5043 5023>,
			<6057 5539 5270 5107 5050 5030>,
			<6036 5522 5241 5107 5056 5035>,
			<6031 5507 5223 5096 5047 5028>,
			<6031 5495 5208 5067 5021 5008>,
			<6035 5487 5199 5055 5011 4999>,
			<6059 5480 5193 5052 5008 4997>,
			<6096 5476 5191 5051 5008 4996>,
			<6129 5478 5192 5052 5008 4997>,
			<6167 5483 5194 5054 5010 4999>,
			<6207 5496 5194 5057 5012 5001>,
			<6250 5530 5193 5061 5016 5003>,
			<6295 5570 5193 5064 5019 5006>,
			<6341 5611 5194 5067 5023 5010>,
			<6390 5658 5197 5070 5027 5013>,
			<6441 5709 5205 5073 5028 5013>,
			<6494 5767 5222 5076 5029 5014>,
			<6545 5831 5242 5075 5028 5012>,
			<6595 5902 5266 5068 5019 5006>,
			<6641 5977 5292 5062 5013 5001>,
			<6680 6054 5319 5059 5010 4999>,
			<6713 6130 5349 5059 5009 4999>,
			<6740 6203 5380 5067 5012 5001>,
			<6772 6267 5401 5067 5009 4997>,
			<6757 6246 5387 5066 5009 4998>,
			<6849 6367 5436 5063 5003 4992>,
			<6987 6532 5513 5075 5009 4998>,
			<7083 6628 5559 5081 5013 5001>,
			<7225 6725 5617 5090 5019 5006>,
			<7448 6845 5688 5102 5025 5014>,
			<7951 6988 5778 5110 5028 5015>,
			<9450 7201 5875 5111 5018 5003>,
			<12670 7688 6025 5113 5016 5002>,
			<20134 9523 6327 5126 5022 5008>,
			<44706 16058 6866 5153 5034 5019>,
			<44706 16058 6866 5153 5034 5019>,
			<44706 16058 6866 5153 5034 5019>;
	};

};
